# MEC1721N_B0_LJ register map
Vendor: Microchip Technology; Series: MEC172x; File version: 0
CPU: CM4 r1p0, little endian, MPU, FPU, 3 interrupt priority bits, 172 interrupts
Registers are 32-bit, read-write, reset 0x0 unless marked. A register's access mark holds for its fields unless they carry their own. Offsets are from the block's base; [hi:lo] are bit positions; {n}, {i} and the like mark numbered series; 'fields as' and 'values as' point back to an identical list.

## ESPI_MEMORY — The eSPI Memory Component is one of two Logical Devices (along with the I/O Component) that provide access to all the registers in the device.
Base 0x400F3800
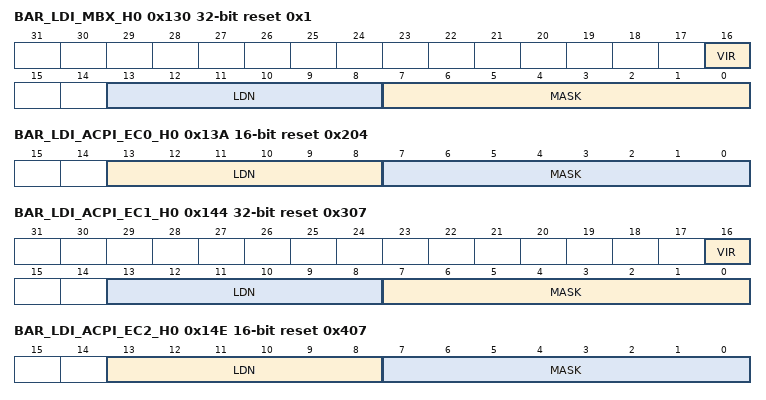
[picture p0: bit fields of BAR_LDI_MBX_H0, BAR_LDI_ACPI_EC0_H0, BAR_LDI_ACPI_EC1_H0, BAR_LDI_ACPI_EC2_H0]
0x130 BAR_LDI_MBX_H0 reset 0x1 — Mailbox Memory Base Address
  [16] VIR — 1=Peripheral Channel I/O for this device is virtualized, and reads and writes are handled in firmware 0=All Peripheral Channel I/O Reads and Writes for this device are completed by hardware.
  [13:8] LDN — These 6 bits are used to specify a logical device number within a bus. This field is multiplied by 400h to provide the address within the peripheral bus address. Logical Device Numbers that do not corresponding to logical devices that are present on the device are invalid.
  [7:0] MASK — These 8 bits are used to mask off address bits in the address match between an eSPI I/O address and the Host Address field of the BARs. A block of up to 256 8-bit registers can be assigned to one base address.
0x13A BAR_LDI_ACPI_EC0_H0 16-bit reset 0x204 — ACPI EC Channel 0 Memory BAR (LSB)
  [13:8] LDN — These 6 bits are used to specify a logical device number within a bus. This field is multiplied by 400h to provide the address within the peripheral bus address. Logical Device Numbers that do not corresponding to logical devices that are present on the device are invalid.
  [7:0] MASK — These 8 bits are used to mask off address bits in the address match between an eSPI I/O address and the Host Address field of the BARs. A block of up to 256 8-bit registers can be assigned to one base address.
0x13C BAR_LDI_ACPI_EC0_H1 16-bit — ACPI EC Channel 0 Memory BAR (MSB)
  [0] VIR — 1=Peripheral Channel I/O for this device is virtualized, and reads and writes are handled in firmware 0=All Peripheral Channel I/O Reads and Writes for this device are completed by hardware.
0x144 BAR_LDI_ACPI_EC1_H0 reset 0x307 — ACPI EC Channel 1 Memory BAR
  fields as BAR_LDI_MBX_H0
0x14E BAR_LDI_ACPI_EC2_H0 16-bit reset 0x407 — ACPI EC Channel 2 Memory BAR (LSB)
  fields as BAR_LDI_ACPI_EC0_H0
0x150 BAR_LDI_ACPI_EC2_H1 16-bit — ACPI EC Channel 2 Memory BAR (MSB)
  fields as BAR_LDI_ACPI_EC0_H1
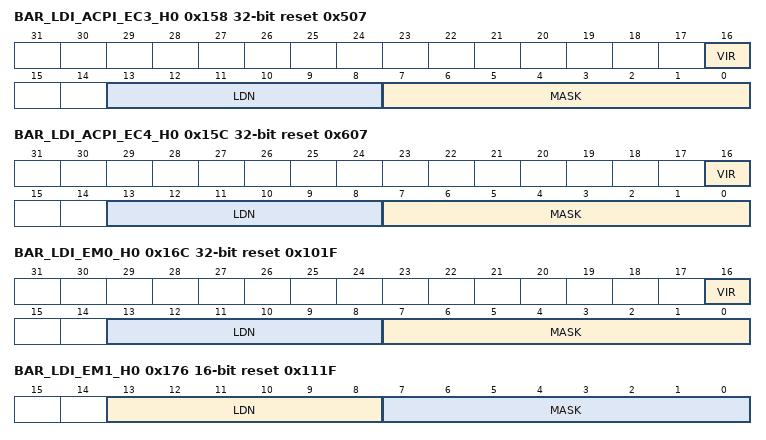
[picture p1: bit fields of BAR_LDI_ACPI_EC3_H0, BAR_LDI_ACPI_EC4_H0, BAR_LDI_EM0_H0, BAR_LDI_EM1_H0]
0x158 BAR_LDI_ACPI_EC3_H0 reset 0x507 — ACPI EC Channel 3 Memory BAR
  fields as BAR_LDI_MBX_H0
0x15C BAR_LDI_ACPI_EC4_H0 reset 0x607 — ACPI EC Channel 4 Memory BAR
  fields as BAR_LDI_MBX_H0
0x160 BAR_LDI_ACPI_EC4_H1 16-bit — ACPI EC Channel 4 Memory BAR (MSB)
  fields as BAR_LDI_ACPI_EC0_H1
0x16C BAR_LDI_EM0_H0 reset 0x101F — Embedded Memory Interface (EMI) 0 Memory Base Address
  fields as BAR_LDI_MBX_H0
0x176 BAR_LDI_EM1_H0 16-bit reset 0x111F — Embedded Memory Interface (EMI) 1 Memory Base Address (LSB)
  fields as BAR_LDI_ACPI_EC0_H0
0x178 BAR_LDI_EM1_H1 16-bit — Embedded Memory Interface (EMI) 1 Memory Base Address (MSB)
  fields as BAR_LDI_ACPI_EC0_H1
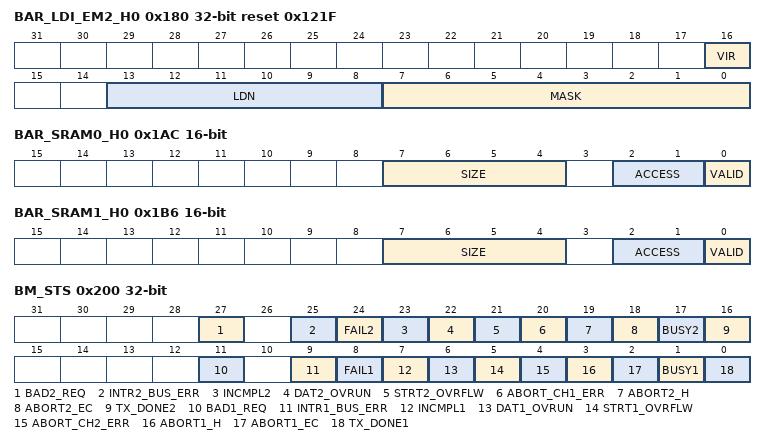
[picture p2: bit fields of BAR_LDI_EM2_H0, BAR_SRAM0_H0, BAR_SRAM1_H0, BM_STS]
0x180 BAR_LDI_EM2_H0 reset 0x121F — Embedded Memory Interface (EMI) 2 Memory Base Address
  fields as BAR_LDI_MBX_H0
0x1AC BAR_SRAM0_H0 16-bit — SRAM 0 Memory Base Address Config
  [7:4] SIZE — This field defines the size of the region mapped from Host Memory address space into the internal address space, in powers of 2. 15=The region is 64KB in extent 14=The region is 32KB in extent ... 1=The region is 2B in extent 0=The region is 1B in extent.
  [2:1] ACCESS — These 2 bits define the access type of access to this SRAM region. 3=Host has Read/write access to the region 2=Host has Write-only access to the region 1=Host has Read-only access to the region 0=Host has no access to this region
  [0] VALID — 1=The BAR is valid and will participate in eSPI matches. 0=The BAR is ignored.
0x1AE BAR_SRAM0_H1 16-bit — SRAM 0 Memory Base Address LSB
  [15:0] ADDR — This is the LSB of the 32-bit field that defines the base address of the internal memory region to which Host accesses to the region starting at RAM eSPI Host Address are mapped. The least significant 2**RAM SIZE bits are ignored.
0x1B0 BAR_SRAM0_H2 — SRAM 0 Memory Base Address MSB
  [15:0] ADDR — This is the MSB of the 32-bit field that defines the base address of the internal memory region to which Host accesses to the region starting at RAM eSPI Host Address are mapped. The least significant 2**RAM SIZE bits are ignored.
0x1B6 BAR_SRAM1_H0 16-bit — SRAM 1 Memory Base Address Config
  fields as BAR_SRAM0_H0
0x1B8 BAR_SRAM1_H1 16-bit — SRAM 1 Memory Base Address LSB
  fields as BAR_SRAM0_H1
0x1BA BAR_SRAM1_H2 16-bit — SRAM 1 Memory Base Address MSB
  [15:0] ADDR — This the MSB of the 32-bit field that defines the base address of the internal memory region to which Host accesses to the region starting at RAM eSPI Host Address are mapped. The least significant 2**RAM SIZE bits are ignored.
0x200 BM_STS — Bus Master Status Register
  [27] BAD2_REQ — This bit is set, and the START request is terminated immediately (BM2_TRANSFER_DONE=1) without triggering traffic, if register contents are invalid at the time the BM2_START bit is written to '1' by firmware. (R/WC) Examples of a Bad Request are: Length of zero, or Length greater than 4K (1000h) Host Address and Length together specifying a request that crosses a 4KByte boundary. This might violate the Scatter/Gather structure of the Host memory, so is not allowed.
  [25] INTR2_BUS_ERR — This bit is set if a transfer on Bus Master Channel 2 is terminated due to a bus error internal to the EC. This can happen if an invalid address is provided in the Bus Master 2 internal Address register. (R/WC)
  [24] FAIL2 — This bit is set if a Layer 3 transaction from Bus Master Channel 2 completes with an Unsuccessful Completion packet from the eSPI Host. For example, this will happen if the START request attempts to read from a forbidden or unmapped address in System Memory. Bad Writes, however, cannot be flagged this way, and will be silently dropped by the eSPI Host without setting this bit. (R/WC)
  [23] INCMPL2 — This bit is set if the transfer on Bus Master Channel 2 completed but an insufficient number of bytes were transferred. Some of the data will not be delivered on the internal bus. (R/WC)
  [22] DAT2_OVRUN — This bit is set if the transfer on Bus Master Channel 2 completed but too many bytes were delivered by the eSPI Host. Some of the data will not be delivered on the internal bus. (R/WC)
  [21] STRT2_OVRFLW — This bit is set if the bit BM2_START in the Bus Master 2 Control Register is written with a 1 while the bit BM2_BUSY is 1. This condition immediately halts the transfer in progress also (BM2_TRANSFER_DONE=1). (R/WC)
  [20] ABORT_CH1_ERR — This bit is set if an error occurs on Bus Master Channel 1 while a Channel 2 transfer is in progress, if the two channels are linked. Linkage occurs when bit BM2_WAIT_BM1_NOT_BUSY in register Bus Master 2 Control Register is set to '1'. No traffic will occur from this channel before the error is posted and the BM2_TRANSFER_DONE bit is set. (R/WC)
  [19] ABORT2_H — A '1' in this bit indicates that the last requested Mastering operation was aborted because Bus Mastering has been disabled by the Host. Bus Mastering is disabled whenever the Peripheral Channel Mastering Enable bit in that register is '0', or the Peripheral Channel Enable bit is '0'. (R/WC)
  [18] ABORT2_EC — This bit is set when the control bit BM2_ABORT in the Bus Master 2 Control Register is written with a 1 during an active transfer. (R/WC)
  [17] BUSY2 — Hardware sets this bit to 1 when the control bit BM2_START in the Bus Master 2 Control Register is written with a 1. This bit is cleared when the transfer completes. This may happen normally, but it is guaranteed to happen also if any of the Error bits in this register section (bits[27:18]) is set by an error condition.
  [16] TX_DONE2 — This bit is set to '1' when a START transfer on Bus Master Channel 2 has completed, and occurs simultaneously with the clearing of the BM2_BUSY bit. This may happen normally, but it is guaranteed to happen also if any of the Error bits in this register section (bits[27:18]) is set by an error condition. At the time that this bit is set to '1', the Error bits are guaranteed to be in their final states, and can be examined. (R/WC)
  [11] BAD1_REQ — This bit is set, and the START request is terminated immediately (BM1_TRANSFER_DONE=1) without triggering traffic, if register contents are invalid at the time the BM1_START bit is written to '1' by firmware. (R/WC) Examples of a Bad Request are: Length of zero Length greater than 4K (1000h) Host Address and Length together specifying a request that crosses a 4KByte boundary. This might violate the Scatter/Gather structure of the Host memory, so is not allowed.
  [9] INTR1_BUS_ERR — This bit is set if a transfer on Bus Master Channel 1 is terminated due to a bus error internal to the EC. This can happen if an invalid address is provided in the Bus Master 1 internal Address register. (R/WC)
  [8] FAIL1 — This bit is set if a Layer 3 transaction from Bus Master Channel 1 completes with an Unsuccessful Completion packet from the eSPI Host. For example, this will happen if the START request attempts to read from a forbidden or unmapped address in System Memory. Bad Writes, however, cannot be flagged this way, and will be silently dropped by the eSPI Host without setting this bit. (R/WC)
  [7] INCMPL1 — This bit is set if the transfer on Bus Master Channel 1 completed but an insufficient number of bytes were transferred. Some of the data will not be delivered on the internal bus. (R/WC)
  [6] DAT1_OVRUN — This bit is set if the transfer on Bus Master Channel 1 completed but too many bytes were delivered by the eSPI Host. Some of the data will not be delivered on the internal bus. (R/WC)
  [5] STRT1_OVRFLW — This bit is set if the bit BM1_START in the Bus Master 1 Control Register is written with a 1 while the bit BM1_BUSY is 1. This condition immediately halts the transfer in progress also (BM1_TRANSFER_DONE=1). (R/WC)
  [4] ABORT_CH2_ERR — This bit is set if an error occurs on Bus Master Channel 2 while a Channel 1 transfer is in progress, if the two channels are linked. Linkage occurs when bit BM1_WAIT_BM2_NOT_BUSY in register Bus Master 1 Control Register is set to '1'. No traffic will occur from this channel before the error is posted and the BM1_TRANSFER_DONE bit is set. (R/WC)
  [3] ABORT1_H — A '1' in this bit indicates that the last requested Mastering operation was aborted because Bus Mastering has been disabled by the Host. Bus Mastering is disabled whenever the Peripheral Channel Mastering Enable bit in that register is '0', or the Peripheral Channel Enable bit is '0'. (R/WC)
  [2] ABORT1_EC — This bit is set when the control bit BM1_ABORT in the Bus Master 1 Control Register is written with a 1 during an active transfer. (R/WC)
  [1] BUSY1 — Hardware sets this bit to 1 when the control bit BM1_START in the Bus Master 1 Control Register is written with a 1. This bit is cleared when the transfer completes. This may happen normally, but it is guaranteed to happen also if any of the Error bits in this register section (bits[11:2]) is set by an error condition.
  [0] TX_DONE1 — This bit is set to '1' when a START transfer on Bus Master Channel 1 has completed, and occurs simultaneously with the clearing of the BM1_BUSY bit. This may happen normally, but it is also guaranteed to happen if any of the Error bits in this register section (bits[11:2]) is set by an error condition. At the time that this bit is set to '1', the Error bits are guaranteed to be in their final states, and can be examined. Firmware is required to clear this bit, by writing '1' to this bit position, before altering any BM1 registers or making a new START request, otherwise interrupts from this block will be unreliable. (R/WC)
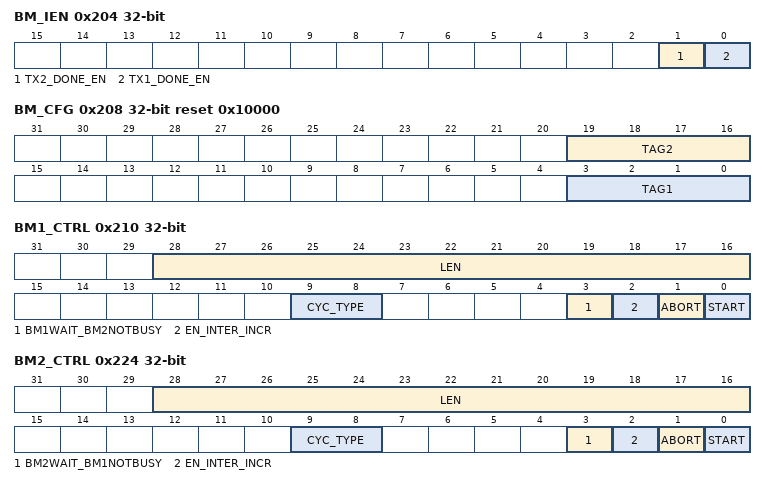
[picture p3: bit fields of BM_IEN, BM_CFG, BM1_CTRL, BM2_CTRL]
0x204 BM_IEN — Bus Master Interrupt Enable Register
  [1] TX2_DONE_EN — When this bit is '1' an interrupt is generated when the bit BM2_TRANSFER_DONE in the Bus Master Status Register is 1. When this bit is '0', the status bit will not generate an interrupt.
  [0] TX1_DONE_EN — When this bit is '1' an interrupt is generated when the bit BM1_TRANSFER_DONE in the Bus Master Status Register is 1. When this bit is '0', the status bit will not generate an interrupt.
0x208 BM_CFG reset 0x10000 — Bus Master Configuration Register
  [19:16] TAG2 — This 4-bit Tag value is included in all eSPI traffic originating from the BM2 Bus Master instance. This bit should not be modified while the bit BM2_BUSY in the Bus Master Status Register is '1'.
  [3:0] TAG1 — This 4-bit Tag value is included in all eSPI traffic originating from the BM1 Bus Master instance. This bit should not be modified while the bit BM1_BUSY in the Bus Master Status Register is '1'.
0x210 BM1_CTRL — Bus Master 1 Control Register
  [28:16] LEN — This field sets the length in bytes of a transfer on Bus Master Channel 1. A value of zero, or a value greater than exactly 4K (0x1000) is illegal. Any length which, in combination with the Bus Master 1 Host Address register, will cause the transfer to cross a 4K-byte boundary in System Memory is also illegal. These illegal settings will cause a request to terminate immediately, with no traffic, and with Bad Request error status posted.
  [9:8] CYC_TYPE — This field provides the cycle type to use inside the eSPI transaction header: 11b=Memory Write, 64-bit addressing 10b=Memory Read, 64-bit addressing 01b=Memory Write, 32-bit addressing 00b=Memory Read, 32-bit addressing.
  [3] BM1WAIT_BM2NOTBUSY — 1=The transfer on Bus Master Channel 1 will be held until a transfer in progress on Bus Master Channel 2 has completed. If that transfer completes unsuccessfully, then this transfer will also terminate, before generating any traffic, with the BM1_ABORTED_BY_CH2_ERROR flag set. 0=The transfer on Bus Master Channel 1 will proceed independently of the status of Bus Master Channel 2.
  [2] EN_INTER_INCR — 1=The internal address will be incremented after each transfer to eSPI 0=The internal address will remain fixed for the entire Bus Master transfer. This may be used to transfer data to or from an on-chip FIFO instead of a region of memory, or to fill a region of Host memory from a single byte value.
  [1] ABORT — A write of '1' to this bit will cause an active transfer on Bus Master Channel 1 to terminate at the next point allowed by the eSPI protocol. A write of 0 has no effect. Reads of this bit return 0. If this bit is written to 1 by firmware, there is no guarantee that any data will have been transferred.
  [0] START — A write of '1' to this bit starts a Bus Master transfer on Bus Master Channel 1. A write of 0 has no effect. Reads of this bit return 0. The transmission will be inhibited if the Peripheral channel is not Ready, as defined in the eSPI Peripheral Channel Ready Register.
0x214 BM1_HOST_ADDR_LSW — Bus Master 1 Host Address Register (DWord 0)
  [31:0] LSDW — This register sets bits [31:0] of the Host address used for a transfer on Bus Master Channel 1. This address, combined with the Length, must not cross a 4K boundary, or else the START request will terminate without traffic, posting the Bad Request error status.
0x218 BM1_HOST_ADDR_MSW — Bus Master 1 Host Address Register (DWord 1)
  [31:0] MSDW — This register sets bits [63:32] of the Host address used for a transfer on Bus Master Channel 1. This address, combined with the Length, must not cross a 4K boundary, or else the START request will terminate without traffic, posting the Bad Request error status.
0x21C BM1_EC_ADDR_LSW — Bus Master 1 Internal Address Register
  [31:2] IN_ADDR — This register sets the internal address to be used for a transfer on Bus Master Channel 1.
0x224 BM2_CTRL — Bus Master 2 Control Register
  [28:16] LEN — This field sets the length in bytes of a transfer on Bus Master Channel 2. A value of zero, or a value greater than exactly 4K (0x1000) is illegal. Any length which, in combination with the Bus Master 2 Host Address register, will cause the transfer to cross a 4K-byte boundary in System Memory is also illegal. These illegal settings will cause a request to terminate immediately, with no traffic, and with Bad Request error status posted.
  [9:8] CYC_TYPE — This field provides the cycle type to use inside the eSPI transaction header: 11b=Memory Write, 64-bit addressing 10b=Memory Read, 64-bit addressing 01b=Memory Write, 32-bit addressing 00b=Memory Read, 32-bit addressing.
  [3] BM2WAIT_BM1NOTBUSY — 1=The transfer on Bus Master Channel 2 will be held until a transfer in progress on Bus Master Channel 1 has completed. If that transfer completes unsuccessfully, then this transfer will also terminate, before generating any traffic, with the BM2_ABORTED_BY_CH1_ERROR flag set. 0=The transfer on Bus Master Channel 2 will proceed independently of the status of Bus Master Channel 1.
  [2] EN_INTER_INCR — 1=The internal address will be incremented after each transfer to eSPI 0=The internal address will remain fixed for the entire Bus Master transfer. This may be used to transfer data to or from an on-chip FIFO instead of a region of memory, or to fill a region of Host memory from a single byte value.
  [1] ABORT — A write of '1' to this bit will cause an active transfer on Bus Master Channel 2 to terminate at the next point allowed by the eSPI protocol. A write of 0 has no effect. Reads of this bit return 0. If this bit is written to 1 by firmware, there is no guarantee that any data will have been transferred.
  [0] START — A write of '1' to this bit starts a Bus Master transfer on Bus Master Channel 2. A write of 0 has no effect. Reads of this bit return 0. The transmission will be inhibited if the Peripheral channel is not Ready, as defined in the eSPI Peripheral Channel Ready Register.
0x228 BM2_HOST_ADDR_LSW — Bus Master 2 Host Address Register (DWord 0)
  [31:0] LSDW — This register sets bits [31:0] of the Host address used for a transfer on Bus Master Channel 2. This address, combined with the Length, must not cross a 4K boundary, or else the START request will terminate without traffic, posting the Bad Request error status.
0x22C BM2_HOST_ADDR_MSW — Bus Master 2 Host Address Register (DWord 1)
  [31:0] MSDW — This register sets bits [63:32] of the Host address used for a transfer on Bus Master Channel 2. This address, combined with the Length, must not cross a 4K boundary, or else the START request will terminate without traffic, posting the Bad Request error status.
0x230 BM2_EC_ADDR_LSW — Bus Master 2 Internal Address Register
  [31:2] IN_ADDR — This register sets the internal address to be used for a transfer on Bus Master Channel 2.
0x330 BAR_LDH_MBX_H0 16-bit — Mailbox Memory BAR Configuration Register (Word 0)
  [0] VALID — 1=The BAR is valid and will participate in eSPI matches. 0=The BAR is ignored.
{0x330+2i} BAR_LDH_MBX_H{i} 16-bit (i=1..4) — Mailbox Memory BAR Configuration Register (Word {i})
  [15:0] ESP_H_ADDR_W{i-1} — Bits[{16i-1}:{16i-16}] of the 64 bits that are used to match eSPI memory addresses.
{0x33A+0xA*i} BAR_LDH_ACPI_EC{i}_H0 16-bit (i=0..4) — ACPI EC Channel {i} Memory BAR Configuration Register (Word 0)
  fields as BAR_LDH_MBX_H0
0x33C BAR_LDH_ACPI_EC0_H1 16-bit reset 0x62 — ACPI EC Channel 0 Memory BAR Configuration Register (Word 1)
  [15:0] ESP_H_ADDR_W0 — Bits[15:0] of the 64 bits that are used to match eSPI memory addresses.
{0x33E+0xA*i} BAR_LDH_ACPI_EC{i}_H2 16-bit (i=0..4) — ACPI EC Channel {i} Memory BAR Configuration Register (Word 2)
  [15:0] ESP_H_ADDR_W1 — Bits[31:16] of the 64 bits that are used to match eSPI memory addresses.
{0x340+0xA*i} BAR_LDH_ACPI_EC{i}_H3 16-bit (i=0..4) — ACPI EC Channel {i} Memory BAR Configuration Register (Word 3)
  [15:0] ESP_H_ADDR_W2 — Bits[47:32] of the 64 bits that are used to match eSPI memory addresses.
{0x342+0xA*i} BAR_LDH_ACPI_EC{i}_H4 16-bit (i=0..4) — ACPI EC Channel {i} Memory BAR Configuration Register (Word 4)
  [15:0] ESP_H_ADDR_W3 — Bits[63:48] of the 64 bits that are used to match eSPI memory addresses.
{0x33C+0xA*i} BAR_LDH_ACPI_EC{i}_H1 16-bit (i=1..4) — ACPI EC Channel {i} Memory BAR Configuration Register (Word 1)
  fields as BAR_LDH_ACPI_EC0_H1
0x36C BAR_LDH_EM0_H0 16-bit — EMI 0 Memory BAR Configuration Register (Word 0)
  fields as BAR_LDH_MBX_H0
0x36E BAR_LDH_EM0_H1 16-bit — EMI 0 Memory BAR Configuration Address Register (Word 1)
  fields as BAR_LDH_ACPI_EC0_H1
0x370 BAR_LDH_EM0_H2 16-bit — EMI 0 Memory BAR Configuration Address Register (Word 2)
  fields as BAR_LDH_ACPI_EC0_H2
0x372 EMI_0_MEM_BAR_CFG_W3 16-bit — EMI 0 Memory BAR Configuration Address Register (Word 3)
  [15:0] ESPI_HOST_ADDRESS_W2 — Bits[47:32] of the 64 bits that are used to match eSPI memory addresses.
0x374 EMI_0_MEM_BAR_CFG_W4 16-bit — EMI 0 Memory BAR Configuration Address Register (Word 4)
  [15:0] ESPI_HOST_ADDRESS_W3 — Bits[63:48] of the 64 bits that are used to match eSPI memory addresses.
0x376 EMI_1_MEM_BAR_CFG_W0 16-bit — EMI 1 Memory BAR Configuration Register (Word 0) )
  fields as BAR_LDH_MBX_H0
{0x376+2i} EMI_1_MEM_BAR_CFG_W{i} 16-bit (i=1..4) — EMI 1 Memory BAR Configuration Register (Word {i}) )
  [15:0] ESPI_HOST_ADDRESS_W{i-1} — Bits[{16i-1}:{16i-16}] of the 64 bits that are used to match eSPI memory addresses.
0x380 EMI_2_MEM_BAR_CFG_W0 16-bit — EMI 2 Memory BAR Configuration Register (Word 0) )
  fields as BAR_LDH_MBX_H0
{0x380+2i} EMI_2_MEM_BAR_CFG_W{i} 16-bit (i=1..4) — EMI 2 Memory BAR Configuration Register (Word {i}) )
  fields as EMI_1_MEM_BAR_CFG_W1
0x3AC SRAM_0_MEM_BAR_CFG_W0 16-bit — SRAM BAR 0 Configuration Register (Word 0) )
  fields as BAR_LDH_MBX_H0
{0x3AC+2i} SRAM_0_MEM_BAR_CFG_W{i} 16-bit (i=1..4) — SRAM BAR 0 Configuration Register (Word {i}) )
  fields as EMI_1_MEM_BAR_CFG_W1
0x3B6 SRAM_1_MEM_BAR_CFG_W0 16-bit — SRAM BAR 1 Configuration Register (Word 0) )
  fields as BAR_LDH_MBX_H0
{0x3B6+2i} SRAM_1_MEM_BAR_CFG_W{i} 16-bit (i=1..4) — SRAM BAR 1 Configuration Register (Word {i}) )
  fields as EMI_1_MEM_BAR_CFG_W1

## Notices in the file
Copyright (c) 2023 Microchip Technology Inc.
SPDX-License-Identifier: Apache-2.0
Licensed under the Apache License, Version 2.0 (the "License");
you may not use this file except in compliance with the License.
You may obtain a copy of the License at
http://www.apache.org/licenses/LICENSE-2.0
Unless required by applicable law or agreed to in writing, software
distributed under the License is distributed on an "AS IS" BASIS,
WITHOUT WARRANTIES OR CONDITIONS OF ANY KIND, either express or implied.
See the License for the specific language governing permissions and
limitations under the License.
